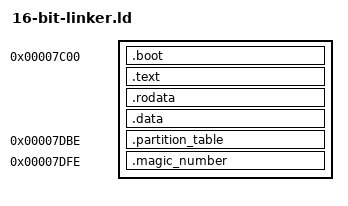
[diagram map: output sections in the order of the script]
ENTRY(_start)

SECTIONS {
    . = 0x500;
    _stack_start = .;
    . = 0x7c00;
    _stack_end = .;

    _mbr_start = .;
    .boot :
    {
        *(.boot .boot.*)
    }
    .text :
    {
        *(.text .text.*)
    }
    .rodata :
    {
        *(.rodata .rodata.*)
    }
    .data :
    {
        *(.rodata .rodata.*)
        *(.data .data.*)
        *(.got .got.*)
    }
    _mbr_end = .;

    . = 0x7c00 + 446;
    .partition_table :
    {
        SHORT(0x0000)       /* partition table entry 0 */
        SHORT(0x0000)       /* partition table entry 1 */
        SHORT(0x0000)       /* partition table entry 2 */
        SHORT(0x0000)       /* partition table entry 3 */
    }

    . = 0x7c00 + 510;

    .magic_number :
    {
        SHORT(0xaa55)       /* magic number for bootable disk */
    }
}
